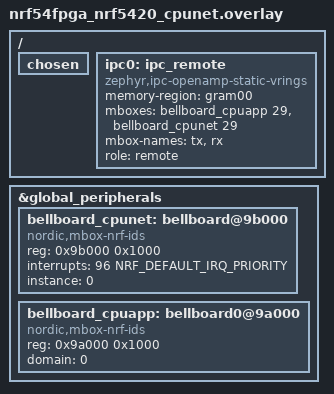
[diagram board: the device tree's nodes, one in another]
/*
 * Copyright (c) 2021 Nordic Semiconductor ASA
 *
 * SPDX-License-Identifier: Apache-2.0
 */

/ {
 	chosen {
 		/delete-property/ nordic,bellboard-cpuapp;
 		/delete-property/ nordic,bellboard-cpunet;
 	};

	ipc0: ipc_remote {
		compatible = "zephyr,ipc-openamp-static-vrings";
		memory-region = <&gram00>;
		mboxes = <&bellboard_cpuapp 29>,
			 <&bellboard_cpunet 29>;
		mbox-names = "tx", "rx";
		role = "remote";
		status = "okay";
	};
};

&global_peripherals {
	/delete-node/ bellboard@9a000;
	/delete-node/ bellboard@9b000;

	bellboard_cpunet: bellboard@9b000 {
		compatible = "nordic,mbox-nrf-ids";
		reg = <0x9b000 0x1000>;
		interrupts = <96 NRF_DEFAULT_IRQ_PRIORITY>;
		instance = <0>;
		status = "okay";
		#mbox-cells = <1>;
	};

	bellboard_cpuapp: bellboard0@9a000 {
		compatible = "nordic,mbox-nrf-ids";
		reg = <0x9a000 0x1000>;
		domain = <0>;
		status = "okay";
		#mbox-cells = <1>;
	};
};
